# FM33A0XXER register map
File version: 1.0
CPU: SC000, little endian, no MPU, no FPU, 3 interrupt priority bits
Registers are 32-bit, read-write, reset 0x0 unless marked. A register's access mark holds for its fields unless they carry their own. Offsets are from the block's base; [hi:lo] are bit positions.

## RTC — RTC module information
Base 0x4001F000
0x00 WER — RTC Write Enable Register
  [0] RTCWE — RTCWE field description
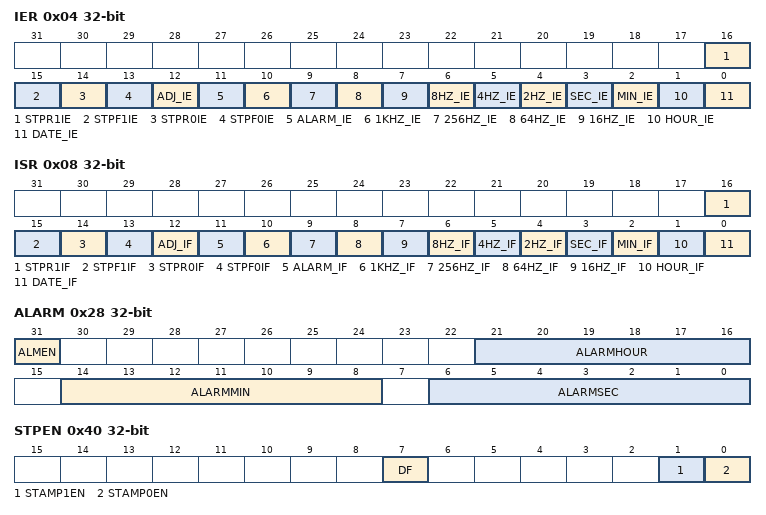
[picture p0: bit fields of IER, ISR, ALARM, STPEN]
0x04 IER — RTC Interrupt Enable Register
  [16] STPR1IE — STPR1IE field description
  [15] STPF1IE — STPF1IE field description
  [14] STPR0IE — STPR0IE field description
  [13] STPF0IE — STPF0IE field description
  [12] ADJ_IE — ADJ_IE field description
  [11] ALARM_IE — ALARM_IE field description
  [10] 1KHZ_IE — 1KHZ_IE field description
  [9] 256HZ_IE — 256HZ_IE field description
  [8] 64HZ_IE — 64HZ_IE field description
  [7] 16HZ_IE — 16HZ_IE field description
  [6] 8HZ_IE — 8HZ_IE field description
  [5] 4HZ_IE — 4HZ_IE field description
  [4] 2HZ_IE — 2HZ_IE field description
  [3] SEC_IE — SEC_IE field description
  [2] MIN_IE — MIN_IE field description
  [1] HOUR_IE — HOUR_IE field description
  [0] DATE_IE — DATE_IE field description
0x08 ISR — RTC Interrupt Status Register
  [16] STPR1IF — STPR1IF field description
  [15] STPF1IF — STPF1IF field description
  [14] STPR0IF — STPR0IF field description
  [13] STPF0IF — STPF0IF field description
  [12] ADJ_IF — ADJ_IF field description
  [11] ALARM_IF — ALARM_IF field description
  [10] 1KHZ_IF — 1KHZ_IF field description
  [9] 256HZ_IF — 256HZ_IF field description
  [8] 64HZ_IF — 64HZ_IF field description
  [7] 16HZ_IF — 16HZ_IF field description
  [6] 8HZ_IF — 8HZ_IF field description
  [5] 4HZ_IF — 4HZ_IF field description
  [4] 2HZ_IF — 2HZ_IF field description
  [3] SEC_IF — SEC_IF field description
  [2] MIN_IF — MIN_IF field description
  [1] HOUR_IF — HOUR_IF field description
  [0] DATE_IF — DATE_IF field description
0x0C BCDSEC — RTC BCD Second register
  [6:0] BCDSEC — BCDSEC field description
0x10 BCDMIN — RTC BCD Minute register
  [6:0] BCDMIN — BCDMIN field description
0x14 BCDHOUR — RTC BCD Hour register
  [5:0] BCDHOUR — BCDHOUR field description
0x18 BCDDATE — RTC BCD Date register
  [5:0] BCDDATE — BCDDATE field description
0x1C BCDWEEK — RTC BCD Week register
  [2:0] BCDWEEK — BCDWEEK field description
0x20 BCDMONTH — RTC BCD Month register
  [4:0] BCDMONTH — BCDMONTH field description
0x24 BCDYEAR — RTC BCD Year register
  [7:0] BCDYEAR — BCDYEAR field description
0x28 ALARM — RTC Alarm Register
  [31] ALMEN — ALMEN field description
  [21:16] ALARMHOUR — ALARMHOUR field description
  [14:8] ALARMMIN — ALARMMIN field description
  [6:0] ALARMSEC — ALARMSEC field description
0x2C TMSEL — RTC Time Mark Select
  [4:0] FSEL — FSEL field description
0x30 ADJUST — RTC time Adjust Register
  [12:0] ADJUST — ADJUST field description
0x34 ADSIGN — RTC time Adjust Sign Register
  [0] ADSIGN — ADSIGN field description
0x40 STPEN — RTC Time Stamp Enable Register
  [7] DF — DF field description
  [1] STAMP1EN — STAMP1EN field description
  [0] STAMP0EN — STAMP0EN field description
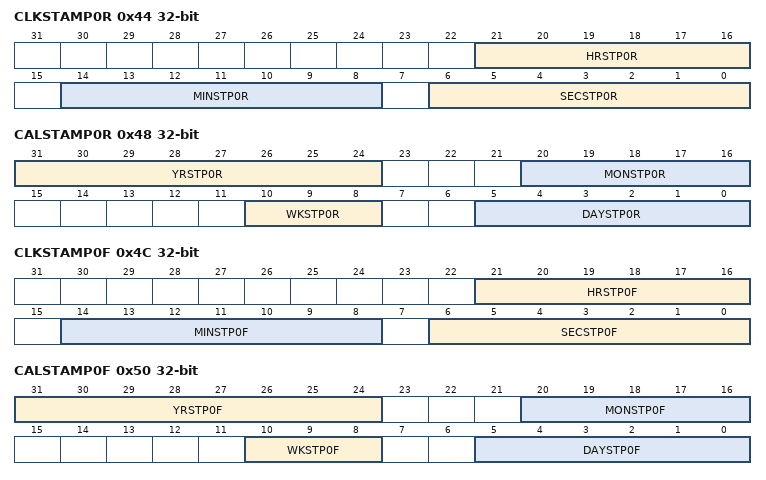
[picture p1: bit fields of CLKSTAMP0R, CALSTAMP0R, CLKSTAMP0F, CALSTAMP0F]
0x44 CLKSTAMP0R — RTC Clock Stamp 0 Rising
  [21:16] HRSTP0R — HRSTP0R field description
  [14:8] MINSTP0R — MINSTP0R field description
  [6:0] SECSTP0R — SECSTP0R field description
0x48 CALSTAMP0R — RTC Calendar Stamp 0 Rising
  [31:24] YRSTP0R — YRSTP0R field description
  [20:16] MONSTP0R — MONSTP0R field description
  [10:8] WKSTP0R — WKSTP0R field description
  [5:0] DAYSTP0R — DAYSTP0R field description
0x4C CLKSTAMP0F — RTC Clock Stamp 0 Falling
  [21:16] HRSTP0F — HRSTP0F field description
  [14:8] MINSTP0F — MINSTP0F field description
  [6:0] SECSTP0F — SECSTP0F field description
0x50 CALSTAMP0F — RTC Calendar Stamp 0 Falling
  [31:24] YRSTP0F — YRSTP0F field description
  [20:16] MONSTP0F — MONSTP0F field description
  [10:8] WKSTP0F — WKSTP0F field description
  [5:0] DAYSTP0F — DAYSTP0F field description
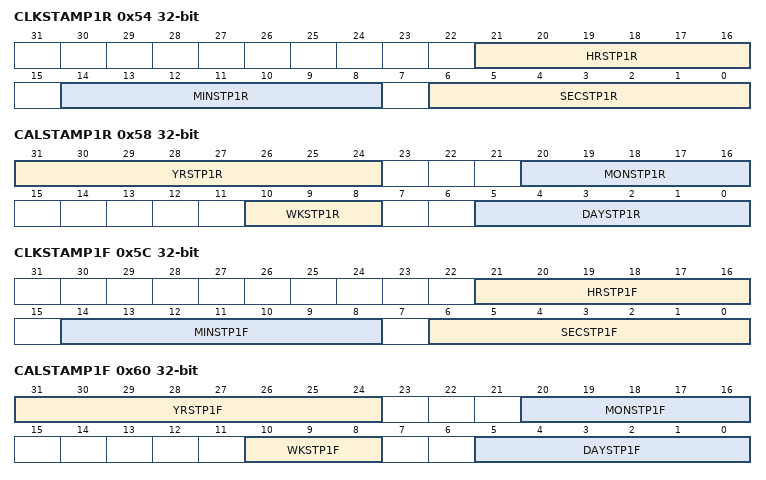
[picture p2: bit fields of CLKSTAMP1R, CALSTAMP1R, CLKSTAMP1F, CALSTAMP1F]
0x54 CLKSTAMP1R — RTC Clock Stamp 1 Rising
  [21:16] HRSTP1R — HRSTP1R field description
  [14:8] MINSTP1R — MINSTP1R field description
  [6:0] SECSTP1R — SECSTP1R field description
0x58 CALSTAMP1R — RTC Calendar Stamp 1 Rising
  [31:24] YRSTP1R — YRSTP1R field description
  [20:16] MONSTP1R — MONSTP1R field description
  [10:8] WKSTP1R — WKSTP1R field description
  [5:0] DAYSTP1R — DAYSTP1R field description
0x5C CLKSTAMP1F — RTC Calendar Stamp 1 Falling
  [21:16] HRSTP1F — HRSTP1F field description
  [14:8] MINSTP1F — MINSTP1F field description
  [6:0] SECSTP1F — SECSTP1F field description
0x60 CALSTAMP1F — RTC Calendar Stamp 1 Falling
  [31:24] YRSTP1F — YRSTP1F field description
  [20:16] MONSTP1F — MONSTP1F field description
  [10:8] WKSTP1F — WKSTP1F field description
  [5:0] DAYSTP1F — DAYSTP1F field description
0x64 ATCCR — RTC Auto Temperature Calibration Control Register
  [0] ACALEN — ACALEN field description
0x68 OFSR — RTC Offset Register
  [10:0] ADOFFSET — ADOFFSET field description
0x6C CALSTEP — RTC Calibration Step Register
  [1:0] CALSTEP — CALSTEP field description
0x70 ATCSR — RTC Auto Calibration Status Register
  [0] AUCALBUSY ro — AUCALBUSY field description
0x74 ADCNT — RTC Calibration Counter
  [8:0] ADJCNT ro — ADJCNT field description
0x78 AUADJUST — RTC Auto Adjust Register
  [12:0] AUADJUST ro — AUADJUST field description
